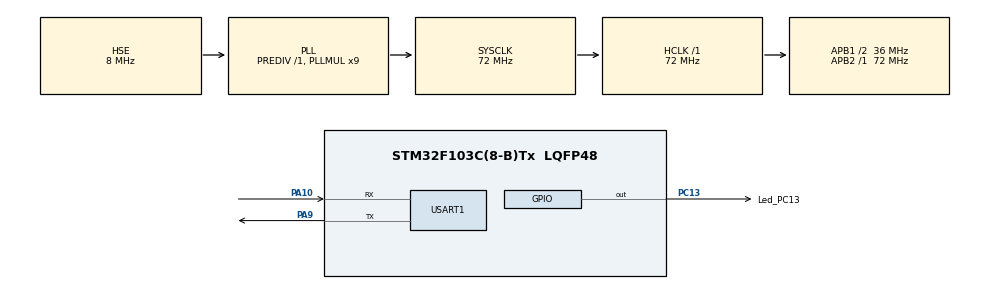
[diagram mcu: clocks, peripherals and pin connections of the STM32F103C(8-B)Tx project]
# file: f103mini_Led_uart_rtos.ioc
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Dma.Request0=USART1_TX
Dma.Request1=USART1_RX
Dma.USART1_RX.1.Direction=DMA_PERIPH_TO_MEMORY
Dma.USART1_RX.1.Instance=DMA1_Channel5
Dma.USART1_RX.1.MemDataAlignment=DMA_MDATAALIGN_HALFWORD
Dma.USART1_RX.1.MemInc=DMA_MINC_ENABLE
Dma.USART1_RX.1.Mode=DMA_CIRCULAR
Dma.USART1_RX.1.PeriphDataAlignment=DMA_PDATAALIGN_BYTE
Dma.USART1_RX.1.PeriphInc=DMA_PINC_DISABLE
Dma.USART1_RX.1.Priority=DMA_PRIORITY_LOW
Dma.USART1_TX.0.Direction=DMA_MEMORY_TO_PERIPH
Dma.USART1_TX.0.Instance=DMA1_Channel4
Dma.USART1_TX.0.MemDataAlignment=DMA_MDATAALIGN_BYTE
Dma.USART1_TX.0.MemInc=DMA_MINC_ENABLE
Dma.USART1_TX.0.Mode=DMA_NORMAL
Dma.USART1_TX.0.PeriphDataAlignment=DMA_PDATAALIGN_BYTE
Dma.USART1_TX.0.PeriphInc=DMA_PINC_DISABLE
Dma.USART1_TX.0.Priority=DMA_PRIORITY_LOW
FREERTOS.Tasks01=defaultTask,0,128,StartDefaultTask,Default
FREERTOS.configTICK_RATE_HZ=100
Mcu.Family=STM32F1
Mcu.Name=STM32F103C(8-B)Tx
Mcu.Package=LQFP48
NVIC.DMA1_Channel4_IRQn=true\:5\:0\:false\:false\:true\:true
NVIC.DMA1_Channel5_IRQn=true\:5\:0\:false\:false\:true\:true
NVIC.PriorityGroup=NVIC_PRIORITYGROUP_4
NVIC.RTC_IRQn=true\:5\:0\:false\:false\:true\:true
NVIC.TIM1_UP_IRQn=true\:0\:0\:false\:false\:true\:false
NVIC.TimeBase=TIM1_UP_IRQn
NVIC.TimeBaseIP=TIM1
NVIC.USART1_IRQn=true\:5\:0\:false\:false\:true\:true
PA10.Mode=Asynchronous
PA10.Signal=USART1_RX
PA13.Mode=Serial_Wire
PA13.Signal=SYS_JTMS-SWDIO
PA14.Mode=Serial_Wire
PA14.Signal=SYS_JTCK-SWCLK
PA9.Mode=Asynchronous
PA9.Signal=USART1_TX
PC13-TAMPER-RTC.GPIO_Label=Led_PC13
PC13-TAMPER-RTC.Signal=GPIO_Output
PC14-OSC32_IN.Mode=LSE-External-Oscillator
PC14-OSC32_IN.Signal=RCC_OSC32_IN
PC15-OSC32_OUT.Mode=LSE-External-Oscillator
PC15-OSC32_OUT.Signal=RCC_OSC32_OUT
PD0-OSC_IN.Mode=HSE-External-Oscillator
PD0-OSC_IN.Signal=RCC_OSC_IN
PD1-OSC_OUT.Mode=HSE-External-Oscillator
PD1-OSC_OUT.Signal=RCC_OSC_OUT
ProjectManager.HeapSize=0x200
ProjectManager.StackSize=0x400
ProjectManager.TargetToolchain=SW4STM32
RCC.AHBFreq_Value=72000000
RCC.APB1CLKDivider=RCC_HCLK_DIV2
RCC.APB1Freq_Value=36000000
RCC.APB1TimFreq_Value=72000000
RCC.APB2Freq_Value=72000000
RCC.APB2TimFreq_Value=72000000
RCC.HCLKFreq_Value=72000000
RCC.HSIState=RCC_HSI_ON
RCC.PLLMUL=RCC_PLL_MUL9
RCC.PLLSourceVirtual=RCC_PLLSOURCE_HSE
RCC.RTCClockSelection=RCC_RTCCLKSOURCE_LSE
RCC.SYSCLKFreq_VALUE=72000000
RCC.SYSCLKSource=RCC_SYSCLKSOURCE_PLLCLK
RCC.USBFreq_Value=72000000
VP_FREERTOS_VS_ENABLE.Mode=Enabled
VP_RTC_No_RTC_Output.Mode=RTC_OUT_NO
VP_SYS_VS_tim1.Mode=TIM1
board=f103mini_Led_uart_rtos

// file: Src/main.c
/**
  ******************************************************************************
  * File Name          : main.c
  * Description        : Main program body
  ******************************************************************************
  *
  * COPYRIGHT(c) 2017 STMicroelectronics
  *
  * Redistribution and use in source and binary forms, with or without modification,
  * are permitted provided that the following conditions are met:
  *   1. Redistributions of source code must retain the above copyright notice,
  *      this list of conditions and the following disclaimer.
  *   2. Redistributions in binary form must reproduce the above copyright notice,
  *      this list of conditions and the following disclaimer in the documentation
  *      and/or other materials provided with the distribution.
  *   3. Neither the name of STMicroelectronics nor the names of its contributors
  *      may be used to endorse or promote products derived from this software
  *      without specific prior written permission.
  *
  * THIS SOFTWARE IS PROVIDED BY THE COPYRIGHT HOLDERS AND CONTRIBUTORS "AS IS"
  * AND ANY EXPRESS OR IMPLIED WARRANTIES, INCLUDING, BUT NOT LIMITED TO, THE
  * IMPLIED WARRANTIES OF MERCHANTABILITY AND FITNESS FOR A PARTICULAR PURPOSE ARE
  * DISCLAIMED. IN NO EVENT SHALL THE COPYRIGHT HOLDER OR CONTRIBUTORS BE LIABLE
  * FOR ANY DIRECT, INDIRECT, INCIDENTAL, SPECIAL, EXEMPLARY, OR CONSEQUENTIAL
  * DAMAGES (INCLUDING, BUT NOT LIMITED TO, PROCUREMENT OF SUBSTITUTE GOODS OR
  * SERVICES; LOSS OF USE, DATA, OR PROFITS; OR BUSINESS INTERRUPTION) HOWEVER
  * CAUSED AND ON ANY THEORY OF LIABILITY, WHETHER IN CONTRACT, STRICT LIABILITY,
  * OR TORT (INCLUDING NEGLIGENCE OR OTHERWISE) ARISING IN ANY WAY OUT OF THE USE
  * OF THIS SOFTWARE, EVEN IF ADVISED OF THE POSSIBILITY OF SUCH DAMAGE.
  *
  ******************************************************************************
  */
#include "stm32f1xx_hal.h"
#include "cmsis_os.h"
#include "dma.h"
#include "rtc.h"
#include "usart.h"
#include "gpio.h"
#include "string.h"

/* USER CODE BEGIN PV */
/* Private variables ---------------------------------------------------------*/

/* USER CODE END PV */

void SystemClock_Config(void);
void Error_Handler(void);
void MX_FREERTOS_Init(void);

/* USER CODE BEGIN PFP */
/* Private function prototypes -----------------------------------------------*/
static void StartThread(void const * argument);

static void LedThread(void const * argument);

void HAL_UART_TxCpltCallback(UART_HandleTypeDef *UartHandle);
void comSend(uint8_t *pData, uint16_t Size);

/* USER CODE END PFP */

/* USER CODE BEGIN 0 */
//RTC_TimeTypeDef sTime;
#define UART_BUFFER_SIZE 30
__IO uint16_t uartBuffer[UART_BUFFER_SIZE];
volatile uint8_t uartCnt=0;
volatile uint8_t txDone=1;

uint8_t aShowTime[50] = {0};

/* USER CODE END 0 */

int main(void)
{

  /* MCU Configuration----------------------------------------------------------*/

  /* Reset of all peripherals, Initializes the Flash interface and the Systick. */
  HAL_Init();

  /* Configure the system clock */
  SystemClock_Config();

  /* Initialize all configured peripherals */
  MX_GPIO_Init();
  MX_DMA_Init();
  MX_RTC_Init();
  MX_USART1_UART_Init();

  /* USER CODE BEGIN 2 */
  osThreadDef(Led_Thread, LedThread, osPriorityNormal, 0, configMINIMAL_STACK_SIZE);
  osThreadCreate (osThread(Led_Thread), NULL);

  osThreadDef(USER_Thread, StartThread, osPriorityNormal, 0, configMINIMAL_STACK_SIZE);
  osThreadCreate (osThread(USER_Thread), NULL);

  memset((uint8_t *)&uartBuffer,(char)0xff,sizeof(uartBuffer));				//��������� ����� 0xFF
  HAL_UART_Receive_DMA(&huart1, (uint8_t *)&uartBuffer, UART_BUFFER_SIZE);	//��������� �����

  /* USER CODE END 2 */

  /* Call init function for freertos objects (in freertos.c) */
  MX_FREERTOS_Init();

  /* Start scheduler */
  osKernelStart();

  /* We should never get here as control is now taken by the scheduler */

  /* Infinite loop */
  while (1)
  {

  }

}

/** System Clock Configuration
*/
void SystemClock_Config(void)
{

  RCC_OscInitTypeDef RCC_OscInitStruct;
  RCC_ClkInitTypeDef RCC_ClkInitStruct;
  RCC_PeriphCLKInitTypeDef PeriphClkInit;

  RCC_OscInitStruct.OscillatorType = RCC_OSCILLATORTYPE_HSE|RCC_OSCILLATORTYPE_LSE;
  RCC_OscInitStruct.HSEState = RCC_HSE_ON;
  RCC_OscInitStruct.HSEPredivValue = RCC_HSE_PREDIV_DIV1;
  RCC_OscInitStruct.LSEState = RCC_LSE_ON;
  RCC_OscInitStruct.PLL.PLLState = RCC_PLL_ON;
  RCC_OscInitStruct.PLL.PLLSource = RCC_PLLSOURCE_HSE;
  RCC_OscInitStruct.PLL.PLLMUL = RCC_PLL_MUL9;
  if (HAL_RCC_OscConfig(&RCC_OscInitStruct) != HAL_OK)
  {
    Error_Handler();
  }

  RCC_ClkInitStruct.ClockType = RCC_CLOCKTYPE_HCLK|RCC_CLOCKTYPE_SYSCLK
                              |RCC_CLOCKTYPE_PCLK1|RCC_CLOCKTYPE_PCLK2;
  RCC_ClkInitStruct.SYSCLKSource = RCC_SYSCLKSOURCE_PLLCLK;
  RCC_ClkInitStruct.AHBCLKDivider = RCC_SYSCLK_DIV1;
  RCC_ClkInitStruct.APB1CLKDivider = RCC_HCLK_DIV2;
  RCC_ClkInitStruct.APB2CLKDivider = RCC_HCLK_DIV1;
  if (HAL_RCC_ClockConfig(&RCC_ClkInitStruct, FLASH_LATENCY_2) != HAL_OK)
  {
    Error_Handler();
  }

  PeriphClkInit.PeriphClockSelection = RCC_PERIPHCLK_RTC;
  PeriphClkInit.RTCClockSelection = RCC_RTCCLKSOURCE_LSE;
  if (HAL_RCCEx_PeriphCLKConfig(&PeriphClkInit) != HAL_OK)
  {
    Error_Handler();
  }

  HAL_SYSTICK_Config(HAL_RCC_GetHCLKFreq()/1000);

  HAL_SYSTICK_CLKSourceConfig(SYSTICK_CLKSOURCE_HCLK);

  /* SysTick_IRQn interrupt configuration */
  HAL_NVIC_SetPriority(SysTick_IRQn, 15, 0);
}

/* USER CODE BEGIN 4 */
static void LedThread(void const * argument)
{
  for(;;)
  {
		HAL_GPIO_WritePin(GPIOC,GPIO_PIN_13,GPIO_PIN_RESET);
    osDelay(100);
		HAL_GPIO_WritePin(GPIOC,GPIO_PIN_13,GPIO_PIN_SET);
		osDelay(900);
  }
}
static void StartThread(void const * argument)
{
	RTC_TimeTypeDef stimestructureget;
	uint8_t ch=0;
  for(;;)
  {
	  	  if (uartBuffer[uartCnt]!=0xffff)
	  	  {
	  		  ch=(uartBuffer[uartCnt] & 0xff);
	  		  uartBuffer[uartCnt]=0xffff;
	  		  uartCnt++;
	  		  if (uartCnt==UART_BUFFER_SIZE) {uartCnt=0;};
	  		  comSend((uint8_t *)&ch,1);
	  		  //txDone=0;
	  		  if (ch==0x74)
	  		  {
	  			  ch=0;
	  			  //osDelay(50);
	  			  //HAL_GPIO_TogglePin(GPIOE, GPIO_PIN_15);
	  			  HAL_RTC_GetTime(&hrtc, &stimestructureget, RTC_FORMAT_BIN);
	  			  sprintf((char *)aShowTime, "%d:%d:%d%s", stimestructureget.Hours, stimestructureget.Minutes, stimestructureget.Seconds,"\r\n");
	  			  //while (txDone!=1) {};
	  			  comSend((uint8_t *)&aShowTime,51);
	  			  //txDone=0;
	  		  }
	  	  }
    osDelay(200);
  }
}

void comSend(uint8_t *pData, uint16_t Size)
{
   while (txDone!=1){}
   HAL_UART_Transmit_DMA(&huart1, pData,Size);
  txDone=0;
}

void HAL_UART_TxCpltCallback(UART_HandleTypeDef *UartHandle)
{
  txDone=1;

//HAL_GPIO_TogglePin(GPIOC, GPIO_PIN_9);

}
/* USER CODE END 4 */

void HAL_TIM_PeriodElapsedCallback(TIM_HandleTypeDef *htim)
{
  if (htim->Instance == TIM1) {
    HAL_IncTick();
  }
}

void Error_Handler(void)
{
  while(1)
  {
  }
}

/************************ (C) COPYRIGHT STMicroelectronics *****END OF FILE****/

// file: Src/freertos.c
/**
  ******************************************************************************
  * File Name          : freertos.c
  * Description        : Code for freertos applications
  ******************************************************************************
  *
  * COPYRIGHT(c) 2017 STMicroelectronics
  *
  * Redistribution and use in source and binary forms, with or without modification,
  * are permitted provided that the following conditions are met:
  *   1. Redistributions of source code must retain the above copyright notice,
  *      this list of conditions and the following disclaimer.
  *   2. Redistributions in binary form must reproduce the above copyright notice,
  *      this list of conditions and the following disclaimer in the documentation
  *      and/or other materials provided with the distribution.
  *   3. Neither the name of STMicroelectronics nor the names of its contributors
  *      may be used to endorse or promote products derived from this software
  *      without specific prior written permission.
  *
  * THIS SOFTWARE IS PROVIDED BY THE COPYRIGHT HOLDERS AND CONTRIBUTORS "AS IS"
  * AND ANY EXPRESS OR IMPLIED WARRANTIES, INCLUDING, BUT NOT LIMITED TO, THE
  * IMPLIED WARRANTIES OF MERCHANTABILITY AND FITNESS FOR A PARTICULAR PURPOSE ARE
  * DISCLAIMED. IN NO EVENT SHALL THE COPYRIGHT HOLDER OR CONTRIBUTORS BE LIABLE
  * FOR ANY DIRECT, INDIRECT, INCIDENTAL, SPECIAL, EXEMPLARY, OR CONSEQUENTIAL
  * DAMAGES (INCLUDING, BUT NOT LIMITED TO, PROCUREMENT OF SUBSTITUTE GOODS OR
  * SERVICES; LOSS OF USE, DATA, OR PROFITS; OR BUSINESS INTERRUPTION) HOWEVER
  * CAUSED AND ON ANY THEORY OF LIABILITY, WHETHER IN CONTRACT, STRICT LIABILITY,
  * OR TORT (INCLUDING NEGLIGENCE OR OTHERWISE) ARISING IN ANY WAY OUT OF THE USE
  * OF THIS SOFTWARE, EVEN IF ADVISED OF THE POSSIBILITY OF SUCH DAMAGE.
  *
  ******************************************************************************
  */

#include "FreeRTOS.h"
#include "task.h"
#include "cmsis_os.h"

osThreadId defaultTaskHandle;

void StartDefaultTask(void const * argument);

void MX_FREERTOS_Init(void); /* (MISRA C 2004 rule 8.1) */

/* Hook prototypes */

/* Init FreeRTOS */

void MX_FREERTOS_Init(void) {

  /* Create the thread(s) */
  /* definition and creation of defaultTask */
  osThreadDef(defaultTask, StartDefaultTask, osPriorityNormal, 0, 128);
  defaultTaskHandle = osThreadCreate(osThread(defaultTask), NULL);

}

/* StartDefaultTask function */
void StartDefaultTask(void const * argument)
{

  for(;;)
  {
    osDelay(1);
  }
}

/************************ (C) COPYRIGHT STMicroelectronics *****END OF FILE****/
